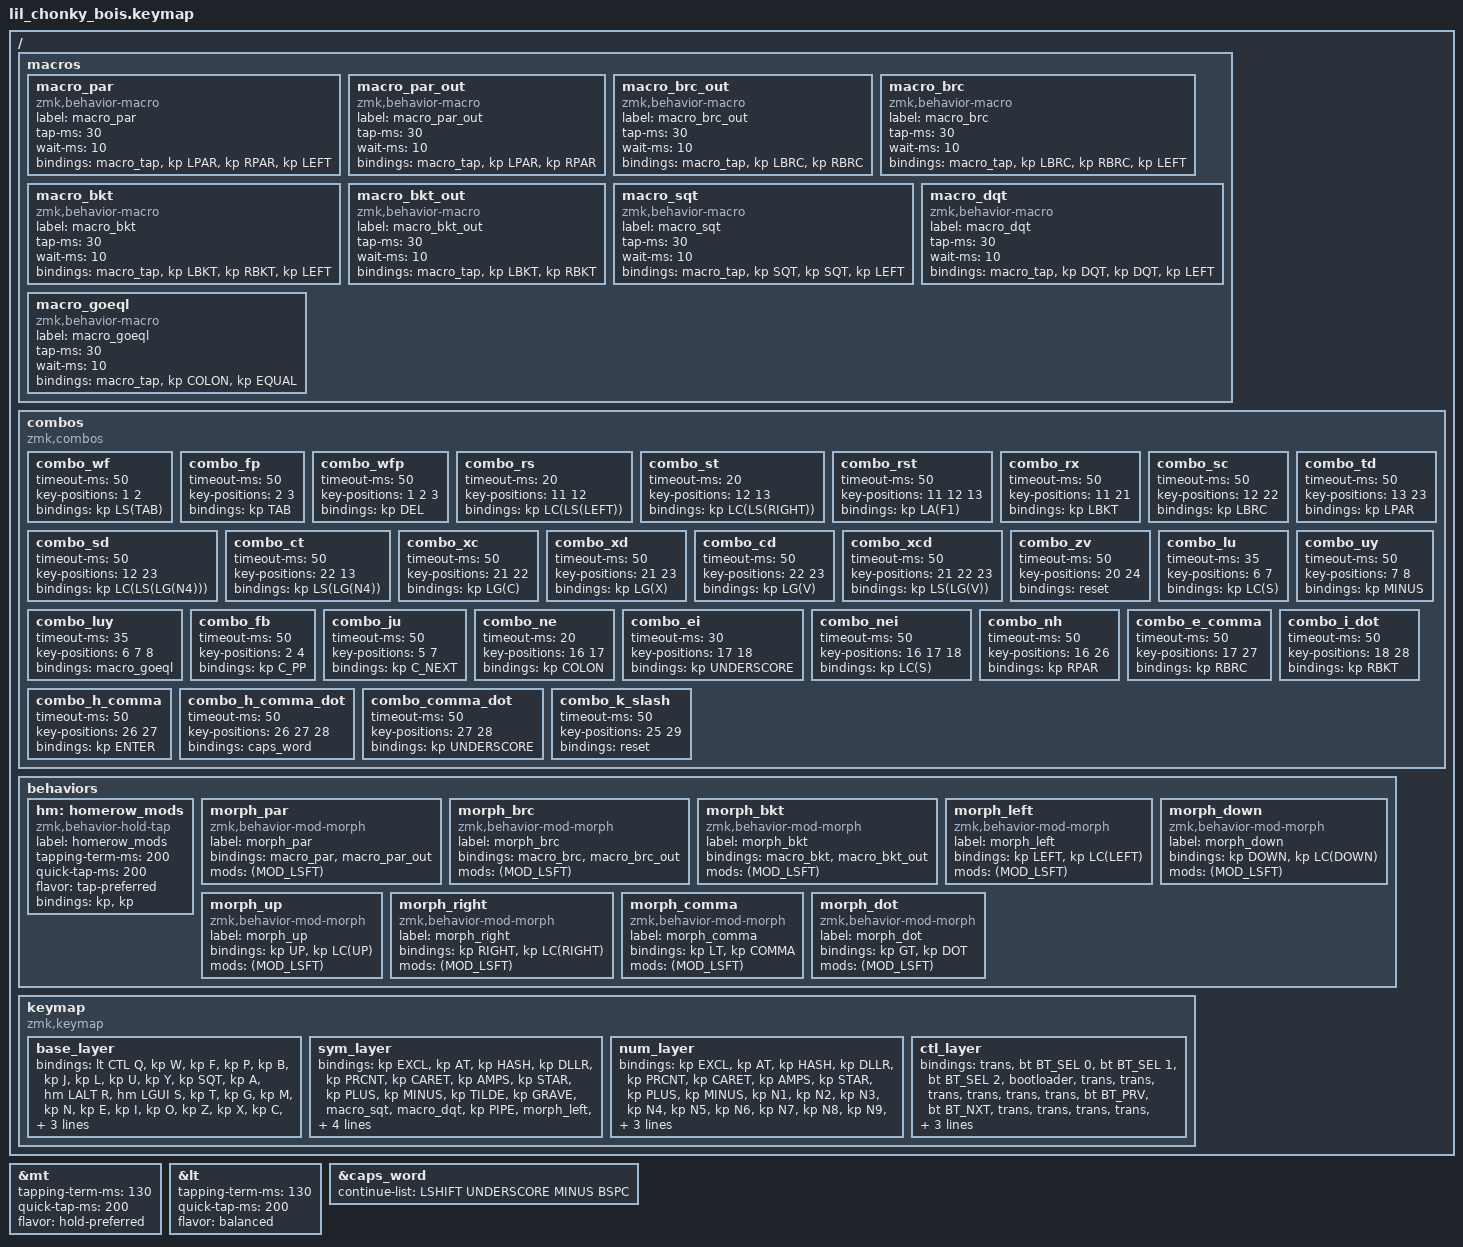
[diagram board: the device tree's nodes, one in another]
// vim: textwidth=0

/*
 * Copyright (c) 2021 The ZMK Contributors
 *
 * SPDX-License-Identifier: MIT
 */

#include <behaviors.dtsi>
#include <dt-bindings/zmk/keys.h>
#include <dt-bindings/zmk/bt.h>

#define DEFAULT 0
#define SYM     1
#define NUM     2
#define CTL     3

&mt {
  tapping-term-ms = <130>;
  quick-tap-ms = <200>;
  flavor = "hold-preferred";
};

&lt {
  tapping-term-ms = <130>;
  quick-tap-ms = <200>;
  flavor = "balanced";
};

&caps_word {
    continue-list = <LSHIFT UNDERSCORE MINUS BSPC>;
};

/ {
    macros {
        macro_par: macro_par {
            label = "macro_par";
            compatible = "zmk,behavior-macro";
            #binding-cells = <0>;
            tap-ms = <30>;
            wait-ms = <10>;
            bindings = <&macro_tap &kp LPAR &kp RPAR &kp LEFT>;
        };
        macro_par_out: macro_par_out {
            label = "macro_par_out";
            compatible = "zmk,behavior-macro";
            #binding-cells = <0>;
            tap-ms = <30>;
            wait-ms = <10>;
            bindings = <&macro_tap &kp LPAR &kp RPAR>;
        };
        macro_brc_out: macro_brc_out {
            label = "macro_brc_out";
            compatible = "zmk,behavior-macro";
            #binding-cells = <0>;
            tap-ms = <30>;
            wait-ms = <10>;
            bindings = <&macro_tap &kp LBRC &kp RBRC>;
        };
        macro_brc: macro_brc {
            label = "macro_brc";
            compatible = "zmk,behavior-macro";
            #binding-cells = <0>;
            tap-ms = <30>;
            wait-ms = <10>;
            bindings = <&macro_tap &kp LBRC &kp RBRC &kp LEFT>;
        };
        macro_bkt: macro_bkt {
            label = "macro_bkt";
            compatible = "zmk,behavior-macro";
            #binding-cells = <0>;
            tap-ms = <30>;
            wait-ms = <10>;
            bindings = <&macro_tap &kp LBKT &kp RBKT &kp LEFT>;
        };
        macro_bkt_out: macro_bkt_out {
            label = "macro_bkt_out";
            compatible = "zmk,behavior-macro";
            #binding-cells = <0>;
            tap-ms = <30>;
            wait-ms = <10>;
            bindings = <&macro_tap &kp LBKT &kp RBKT>;
        };
        macro_sqt: macro_sqt {
            label = "macro_sqt";
            compatible = "zmk,behavior-macro";
            #binding-cells = <0>;
            tap-ms = <30>;
            wait-ms = <10>;
            bindings = <&macro_tap &kp SQT &kp SQT &kp LEFT>;
        };
        macro_dqt: macro_dqt {
            label = "macro_dqt";
            compatible = "zmk,behavior-macro";
            #binding-cells = <0>;
            tap-ms = <30>;
            wait-ms = <10>;
            bindings = <&macro_tap &kp DQT &kp DQT &kp LEFT>;
        };
        macro_goeql: macro_goeql {
				label = "macro_goeql";
				compatible = "zmk,behavior-macro";
				#binding-cells = <0>;
				tap-ms = <30>;
				wait-ms = <10>;
				bindings = <&macro_tap &kp COLON &kp EQUAL>;
		  };
    };

    /*
    available combos
    he <- use 25 ms timeout
    n,
    */
    combos {
        compatible = "zmk,combos";
        combo_wf {
            timeout-ms = <50>;
            key-positions = <1 2>;
            bindings = <&kp LS(TAB)>;
        };
        combo_fp {
            timeout-ms = <50>;
            key-positions = <2 3>;
            bindings = <&kp TAB>;
        };
        /* combo_del { */
        /*     timeout-ms = <50>; */
        /*     key-positions = <1 3>;
        /*     bindings = <&kp DEL>; */
        /* }; */
        combo_wfp {
            timeout-ms = <50>;
            key-positions = <1 2 3>;
            bindings = <&kp DEL>;
        };
        combo_rs {
            timeout-ms = <20>;
            key-positions = <11 12>;
            bindings = <&kp LC(LS(LEFT))>;
        };
        combo_st {
            timeout-ms = <20>;
            key-positions = <12 13>;
            bindings = <&kp LC(LS(RIGHT))>;
        };
        combo_rst {
            timeout-ms = <50>;
            key-positions = <11 12 13>;
            bindings = <&kp LA(F1)>; // FIXME: doesn't work on linux actually, and diff on mac, maybe set binding to the same?
        };
        combo_rx {
            timeout-ms = <50>;
            key-positions = <11 21>;
            bindings = <&kp LBKT>;
        };
        combo_sc {
            timeout-ms = <50>;
            key-positions = <12 22>;
            bindings = <&kp LBRC>;
        };
        combo_td {
            timeout-ms = <50>;
            key-positions = <13 23>;
            bindings = <&kp LPAR>;
        };
        combo_sd {
            timeout-ms = <50>;
            key-positions = <12 23>;
            bindings = <&kp LC(LS(LG(N4)))>; // screenshot copy
        };
        combo_ct {
            timeout-ms = <50>;
            key-positions = <22 13>;
            bindings = <&kp LS(LG(N4))>; // screenshot file
        };
        combo_xc {
            timeout-ms = <50>;
            key-positions = <21 22>;
            bindings = <&kp LG(C)>;
        };
        combo_xd {
            timeout-ms = <50>;
            key-positions = <21 23>;
            bindings = <&kp LG(X)>;
        };
        combo_cd {
            timeout-ms = <50>;
            key-positions = <22 23>;
            bindings = <&kp LG(V)>;
        };
        combo_xcd {
            timeout-ms = <50>;
            key-positions = <21 22 23>;
            bindings = <&kp LS(LG(V))>;
        };
        combo_zv {
            timeout-ms = <50>;
            key-positions = <20 24>;
            bindings = <&reset>;
        };
        combo_lu {
            timeout-ms = <35>;
            key-positions = <6 7>;
            bindings = <&kp LC(S)>;
        };
        combo_uy {
            timeout-ms = <50>;
            key-positions = <7 8>;
            bindings = <&kp MINUS>;
        };
        combo_luy {
            timeout-ms = <35>;
            key-positions = <6 7 8 >;
            bindings = <&macro_goeql>;
        };
        combo_fb {
            timeout-ms = <50>;
            key-positions = <2 4>;
            bindings = <&kp C_PP>;
        };
        combo_ju {
            timeout-ms = <50>;
            key-positions = <5 7>;
            bindings = <&kp C_NEXT>;
        };
        combo_ne {
            timeout-ms = <20>;
            key-positions = <16 17>;
            bindings = <&kp COLON>;
        };
        combo_ei {
          timeout-ms = <30>;
          key-positions = <17 18>;
          bindings = <&kp UNDERSCORE>;
        };
        /* combo_eh { */
        /*   timeout-ms = <35>; */
        /*   key-positions = <17 26>; */
        /*   bindings = <&kp ?>;
        /* }; */
        combo_nei {
            timeout-ms = <50>;
            key-positions = <16 17 18>;
            bindings = <&kp LC(S)>; // FIXME: something else
        };
        combo_nh {
            timeout-ms = <50>;
            key-positions = <16 26>;
            bindings = <&kp RPAR>;
        };
        combo_e_comma {
            timeout-ms = <50>;
            key-positions = <17 27>;
            bindings = <&kp RBRC>;
        };
        combo_i_dot {
            timeout-ms = <50>;
            key-positions = <18 28>;
            bindings = <&kp RBKT>;
        };
        combo_h_comma {
            timeout-ms = <50>;
            key-positions = <26 27>;
            bindings = <&kp ENTER>;
        };
        combo_h_comma_dot {
            timeout-ms = <50>;
            key-positions = <26 27 28>;
            bindings = <&caps_word>; // FIXME: I don't really use this, something else
        };
        combo_comma_dot {
            timeout-ms = <50>;
            key-positions = <27 28>;
            bindings = <&kp UNDERSCORE>; // FIXME: something else maybe <> macro?
        };
        combo_k_slash {
            timeout-ms = <50>;
            key-positions = <25 29>;
            bindings = <&reset>;
        };
    };

    behaviors {
        hm: homerow_mods {
            compatible = "zmk,behavior-hold-tap";
            label = "homerow_mods";
            #binding-cells = <2>;
            tapping-term-ms = <200>;
            quick-tap-ms = <200>;
            flavor = "tap-preferred";
            bindings = <&kp>, <&kp>;
        };
        morph_par: morph_par {
            compatible = "zmk,behavior-mod-morph";
            label = "morph_par";
            #binding-cells = <0>;
            bindings = <&macro_par>, <&macro_par_out>;
            mods = <(MOD_LSFT)>;
        };
        morph_brc: morph_brc {
            compatible = "zmk,behavior-mod-morph";
            label = "morph_brc";
            #binding-cells = <0>;
            bindings = <&macro_brc>, <&macro_brc_out>;
            mods = <(MOD_LSFT)>;
        };
        morph_bkt: morph_bkt {
            compatible = "zmk,behavior-mod-morph";
            label = "morph_bkt";
            #binding-cells = <0>;
            bindings = <&macro_bkt>, <&macro_bkt_out>;
            mods = <(MOD_LSFT)>;
        };
        morph_left: morph_left {
            compatible = "zmk,behavior-mod-morph";
            label = "morph_left";
            #binding-cells = <0>;
            bindings = <&kp LEFT>, <&kp LC(LEFT)>;
            mods = <(MOD_LSFT)>;
        };
        morph_down: morph_down {
            compatible = "zmk,behavior-mod-morph";
            label = "morph_down";
            #binding-cells = <0>;
            bindings = <&kp DOWN>, <&kp LC(DOWN)>;
            mods = <(MOD_LSFT)>;
        };
        morph_up: morph_up {
            compatible = "zmk,behavior-mod-morph";
            label = "morph_up";
            #binding-cells = <0>;
            bindings = <&kp UP>, <&kp LC(UP)>;
            mods = <(MOD_LSFT)>;
        };
        morph_right: morph_right {
            compatible = "zmk,behavior-mod-morph";
            label = "morph_right";
            #binding-cells = <0>;
            bindings = <&kp RIGHT>, <&kp LC(RIGHT)>;
            mods = <(MOD_LSFT)>;
        };
        morph_comma: morph_comma {
            compatible = "zmk,behavior-mod-morph";
            label = "morph_comma";
            #binding-cells = <0>;
            bindings = <&kp LT>, <&kp COMMA>;
            mods = <(MOD_LSFT)>;
        };
        morph_dot: morph_dot {
            compatible = "zmk,behavior-mod-morph";
            label = "morph_dot";
            #binding-cells = <0>;
            bindings = <&kp GT>, <&kp DOT>;
            mods = <(MOD_LSFT)>;
        };
    };

    keymap {
		compatible = "zmk,keymap";

		base_layer {
			bindings = <
			  // row 1
			  &lt CTL Q
			  &kp W
			  &kp F
			  &kp P
			  &kp B

			  &kp J
			  &kp L
			  &kp U
			  &kp Y
			  &kp SQT

			  // row 2
			  &kp A
			  &hm LALT R
			  &hm LGUI S
			  &kp T
			  &kp G

			  &kp M
			  &kp N
			  &kp E
			  &kp I
			  &kp O

			  // row 3
			  &kp Z
			  &kp X
			  &kp C
			  &kp D
			  &kp V

			  &kp K
			  &kp H
			  &kp COMMA
			  &kp DOT
			  &kp SLASH

			  // row thumbs
			  &mt LCTRL ESC
			  &mt LSHFT BSPC
			  &lt SYM SPACE
			  &lt NUM MINUS // TODO: Don't think I need this, maybe back to alt?
			>;
		};

		/* &kp C_MUTE */
		/* &kp C_SLEEP */
		sym_layer {
			bindings = <
			   // row 1
            // FIXME: don't think these all need to be morphs, got a good number layer know thats
            // better
				&kp EXCL
				&kp AT
				&kp HASH
				&kp DLLR
				&kp PRCNT

				&kp CARET
				&kp AMPS
				&kp STAR
				&kp PLUS
				&kp MINUS

				// row 2
				&kp TILDE
				&kp GRAVE
				&macro_sqt
				&macro_dqt
				&kp PIPE

				&morph_left
				&morph_down
				&morph_up
				&morph_right
				&kp BSLH // this actually makes sense i think easier to hit than mod-/

				// row 3
				&kp TILDE // dupe, maybe something else? macro?
				&macro_bkt
				&macro_brc
				&macro_par
				&kp SEMI

				&kp COLON
				&kp EQUAL
				&morph_comma
				&morph_dot
				&trans

				// row thumbs
				&trans
				&trans
				&trans // being held
				&trans
			>;
		};

		num_layer {
			bindings = <
				// row 1
				&kp EXCL
				&kp AT
				&kp HASH
				&kp DLLR
				&kp PRCNT

            &kp CARET
				&kp AMPS
				&kp STAR
				&kp PLUS
				&kp MINUS

				// row 2
				&kp N1
				&kp N2
				&kp N3
				&kp N4
				&kp N5

				&kp N6
				&kp N7
				&kp N8
				&kp N9
				&kp N0

				// row 3
				&trans
				&trans
				&trans
				&trans
				&trans

				&trans
				&trans
				&trans
				&trans
				&trans

				// row thumbs
				&trans
				&trans
				&trans
				&trans
			>;
		};

		ctl_layer {
			bindings = <
				// row 1
				&trans
				&bt BT_SEL 0
				&bt BT_SEL 1
				&bt BT_SEL 2
				&bootloader

				&trans
				&trans
				&trans
				&trans

				// row 2
				&trans
				&trans
				&bt BT_PRV
				&bt BT_NXT
				&trans

				&trans
				&trans
				&trans
				&trans
				&trans

				// row 3
				&trans
				&trans
				&trans
				&trans
				&bt BT_CLR

				&trans
				&trans
				&trans
				&trans
				&trans

				// row thumbs
				&trans
				&trans
				&trans
				&trans
			>;
		};
    };
};
